# G32R502 register map
Vendor: Geehy Semiconductor Co., Ltd.; Series: G32R5; File version: 1.0
CPU: CM52 r0p1, little endian, MPU, FPU, DSP, VTOR, 4 interrupt priority bits
Registers are 32-bit, read-write, reset 0x0 unless marked. A register's access mark holds for its fields unless they carry their own. Offsets are from the block's base; [hi:lo] are bit positions; {n}, {i} and the like mark numbered series; 'fields as' and 'values as' point back to an identical list.

## CPU — CPU_REGS
Base 0x40013600
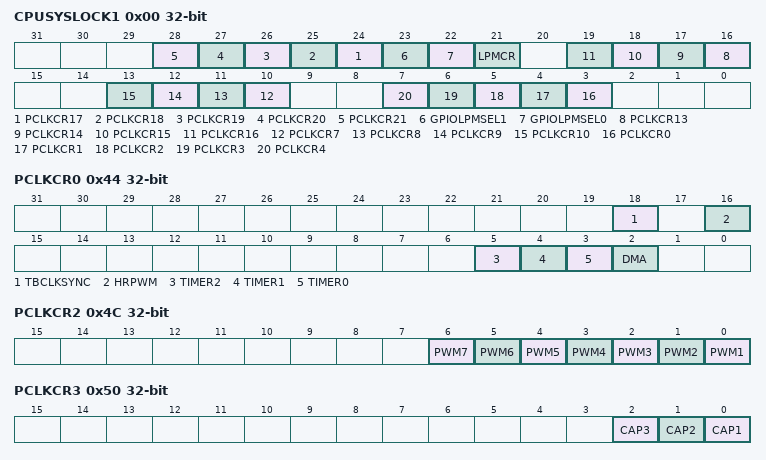
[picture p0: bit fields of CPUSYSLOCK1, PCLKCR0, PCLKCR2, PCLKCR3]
0x00 CPUSYSLOCK1 — Lock bit for CPUSYS registers
  [n+7] PCLKCR{n} (n=17..21) — Lock bit for PCLKCR{n} Register
  [23] GPIOLPMSEL1 — Lock bit for GPIOLPMSEL1 Register
  [22] GPIOLPMSEL0 — Lock bit for GPIOLPMSEL0 Register
  [21] LPMCR — Lock bit for LPMCR Register
  [n+3] PCLKCR{n} (n=13..16) — Lock bit for PCLKCR{n} Register
  [n+3] PCLKCR{n} (n=7..10) — Lock bit for PCLKCR{n} Register
  [n+3] PCLKCR{n} (n=0..4) — Lock bit for PCLKCR{n} Register
0x44 PCLKCR0 — Peripheral Clock Gating Registers
  [18] TBCLKSYNC — PWM Time Base Clock sync
  [16] HRPWM — HRPWM Clock Enable Bit
  [5] TIMER2 — TIMER2 Clock Enable bit
  [4] TIMER1 — TIMER1 Clock Enable bit
  [3] TIMER0 — TIMER0 Clock Enable bit
  [2] DMA — DMA Clock Enable bit
0x4C PCLKCR2 — Peripheral Clock Gating Registers
  [n-1] PWM{n} (n=1..7) — PWM{n} Clock Enable bit
0x50 PCLKCR3 — Peripheral Clock Gating Registers
  [2] CAP3 — CAP3 Clock Enable bit
  [1] CAP2 — CAP2 Clock Enable bit
  [0] CAP1 — CAP1 Clock Enable bit
0x54 PCLKCR4 — Peripheral Clock Gating Registers
  [0] QEP1 — QEP1 Clock Enable bit
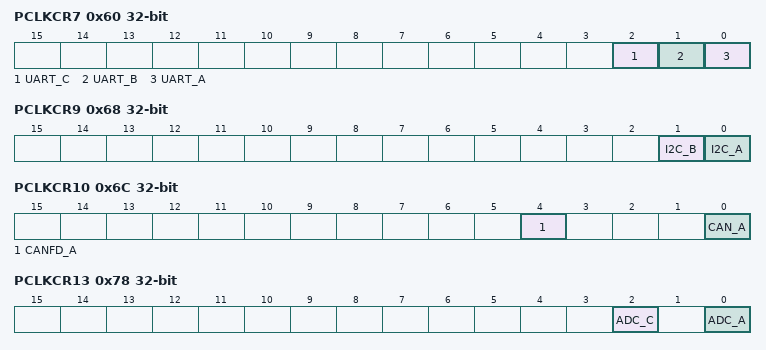
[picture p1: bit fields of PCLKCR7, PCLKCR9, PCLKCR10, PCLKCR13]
0x60 PCLKCR7 — Peripheral Clock Gating Registers
  [2] UART_C — UART_C Clock Enable bit
  [1] UART_B — UART_B Clock Enable bit
  [0] UART_A — UART_A Clock Enable bit
0x64 PCLKCR8 — Peripheral Clock Gating Registers
  [0] SPI_A — SPI_A Clock Enable bit
0x68 PCLKCR9 — Peripheral Clock Gating Registers
  [1] I2C_B — I2C_B Clock Enable bit
  [0] I2C_A — I2C_A Clock Enable bit
0x6C PCLKCR10 — Peripheral Clock Gating Registers
  [4] CANFD_A — CANFDA Clock Enable bit
  [0] CAN_A — CAN_A Clock Enable bit
0x78 PCLKCR13 — Peripheral Clock Gating Registers
  [2] ADC_C — ADC_C Clock Enable bit
  [0] ADC_A — ADC_A Clock Enable bit
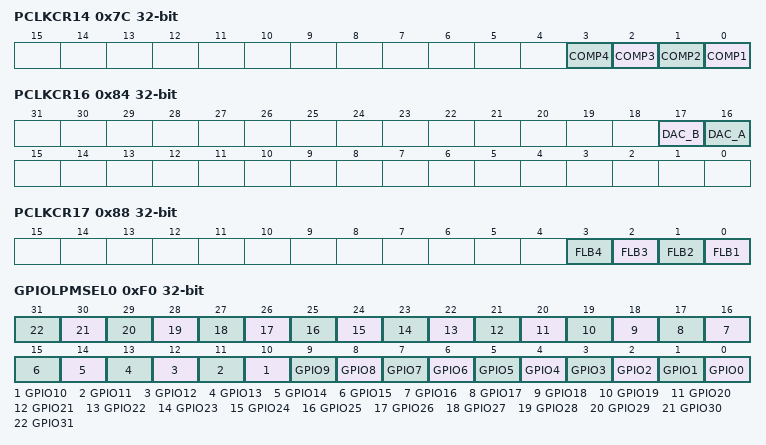
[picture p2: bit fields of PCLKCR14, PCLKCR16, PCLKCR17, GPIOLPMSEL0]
0x7C PCLKCR14 — Peripheral Clock Gating Registers
  [n-1] COMP{n} (n=1..4) — COMP{n}CLKEN Clock Enable bit
0x84 PCLKCR16 — Peripheral Clock Gating Registers
  [17] DAC_B — DAC_B Clock Enable bit
  [16] DAC_A — DAC_A Clock Enable bit
0x88 PCLKCR17 — Peripheral Clock Gating Registers
  [n-1] FLB{n} (n=1..4) — FLB{n} Clock Enable bit
0x90 PCLKCR19 — Peripheral Clock Gating Registers
  [0] LIN_A — LIN_A Clock Enable bit
0x94 PCLKCR20 — Peripheral Clock Gating Registers
  [0] PMBUS_A — PMBUS_A Clock Enable bit
0x98 PCLKCR21 — Peripheral Clock Gating Registers
  [0] DCCOMP_0 — DCCOMP0 Clock Enable
0xEC LPMCR — LPM Control Register
  [1:0] LPM — These bits set the low power mode for the device
0xF0 GPIOLPMSEL0 — GPIO LPM Wakeup select registers
  [n] GPIO{n} (n=0..31) — Pin is connected/disconnected from LPM circuit
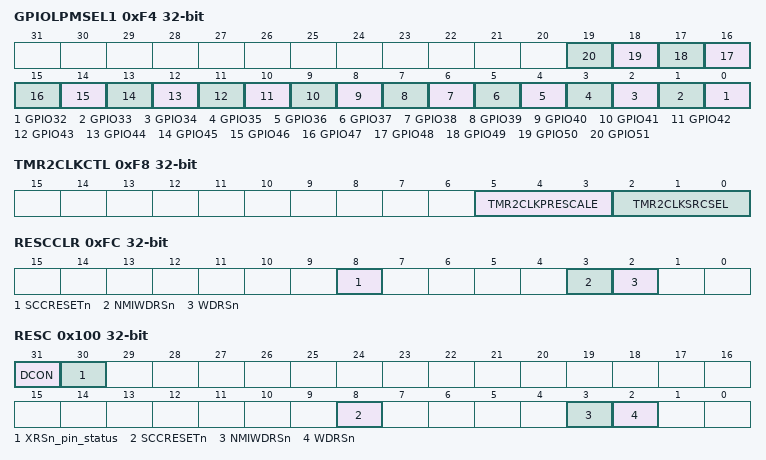
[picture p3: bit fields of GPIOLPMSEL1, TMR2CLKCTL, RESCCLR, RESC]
0xF4 GPIOLPMSEL1 — GPIO LPM Wakeup select registers
  [n-32] GPIO{n} (n=32..51) — Pin is connected/disconnected from LPM circuit
0xF8 TMR2CLKCTL — Timer2 Clock Measurement functionality control register
  [5:3] TMR2CLKPRESCALE — Timer 2 Clock Pre-Scale Value
  [2:0] TMR2CLKSRCSEL — Timer 2 Clock Source Select Bit
0xFC RESCCLR wo — Reset Cause Clear Register
  [8] SCCRESETn — Clear bit for corresponding status bit in RESC
  [3] NMIWDRSn — Clear bit for corresponding status bit in RESC
  [2] WDRSn — Clear bit for corresponding status bit in RESC
0x100 RESC ro — Reset Cause register
  [31] DCON — debugger connection to the Arm Cortex-M52 CPU Flag
  [30] XRSn_pin_status
  [8] SCCRESETn — If this bit is set, indicates that the device was reset by SCCRESETn (fired by DCS)
  [3] NMIWDRSn — If this bit is set, indicates that the device was reset by NMIWDRSn
  [2] WDRSn — If this bit is set, indicates that the device was reset by WDRSn

## PERIPH — PERIPH_REGS
Base 0x40013800
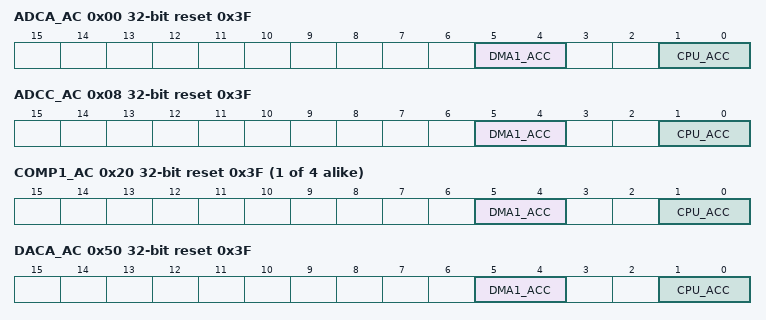
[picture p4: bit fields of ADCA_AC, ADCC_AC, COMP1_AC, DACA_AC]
0x00 ADCA_AC reset 0x3F — ADCA Master Access Control Register
  [5:4] DMA1_ACC — Defines Access control definition for the DMA1
  [1:0] CPU_ACC — Defines Access control definition for the CPU
0x08 ADCC_AC reset 0x3F — ADCC Master Access Control Register
  fields as ADCA_AC
{0x1C+4i} COMP{i}_AC reset 0x3F (i=1..4) — COMP{i} Master Access Control Register
  fields as ADCA_AC
0x50 DACA_AC reset 0x3F — DACA Master Access Control Register
  fields as ADCA_AC
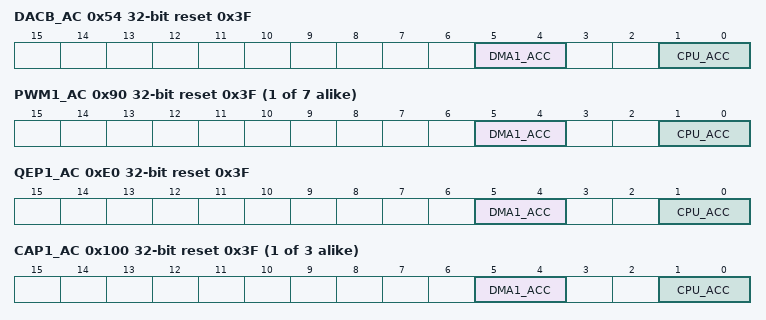
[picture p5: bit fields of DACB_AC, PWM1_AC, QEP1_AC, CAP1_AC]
0x54 DACB_AC reset 0x3F — DACB Master Access Control Register
  fields as ADCA_AC
{0x8C+4i} PWM{i}_AC reset 0x3F (i=1..7) — PWM{i} Master Access Control Register
  fields as ADCA_AC
0xE0 QEP1_AC reset 0x3F — QEP1 Master Access Control Register
  fields as ADCA_AC
{0xFC+4i} CAP{i}_AC reset 0x3F (i=1..3) — CAP{i} Master Access Control Register
  fields as ADCA_AC
{0x15C+4i} FLB{i}_AC reset 0x3F (i=1..4) — FLB{i} Master Access Control Register
  [1:0] CPU_ACC — Defines Access control definition for the CPU
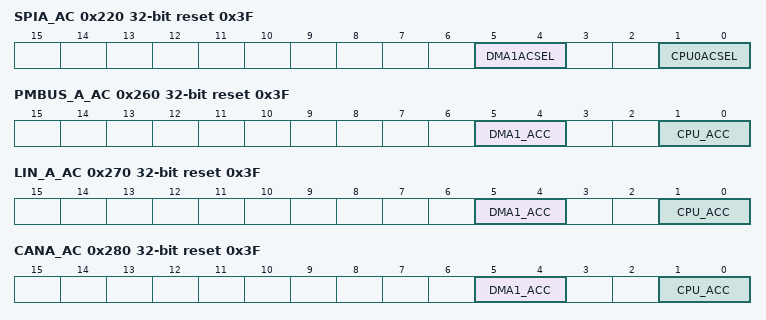
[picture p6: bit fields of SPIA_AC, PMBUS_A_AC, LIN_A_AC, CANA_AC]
0x220 SPIA_AC reset 0x3F — SPIA Master Access Control Register
  [5:4] DMA1ACSEL — DMA1 access permission Select
  [1:0] CPU0ACSEL — CPU0 access permission Select
0x260 PMBUS_A_AC reset 0x3F — PMBUSA Master Access Control Register
  fields as ADCA_AC
0x270 LIN_A_AC reset 0x3F — LINA Master Access Control Register
  fields as ADCA_AC
0x280 CANA_AC reset 0x3F — CANA Master Access Control Register
  fields as ADCA_AC
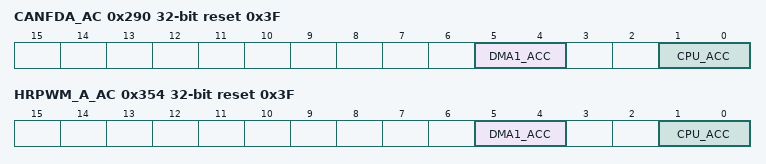
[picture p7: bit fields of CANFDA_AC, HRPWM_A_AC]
0x290 CANFDA_AC reset 0x3F — CANFDA Master Access Control Register
  fields as ADCA_AC
0x354 HRPWM_A_AC reset 0x3F — HRPWM Master Access Control Register
  fields as ADCA_AC
0x3FC PERIPH_AC_LOCK — Lock Register to stop Write access to peripheral Access register.
  [0] LOCK_AC_WR — Lock control for Access control registers write.
